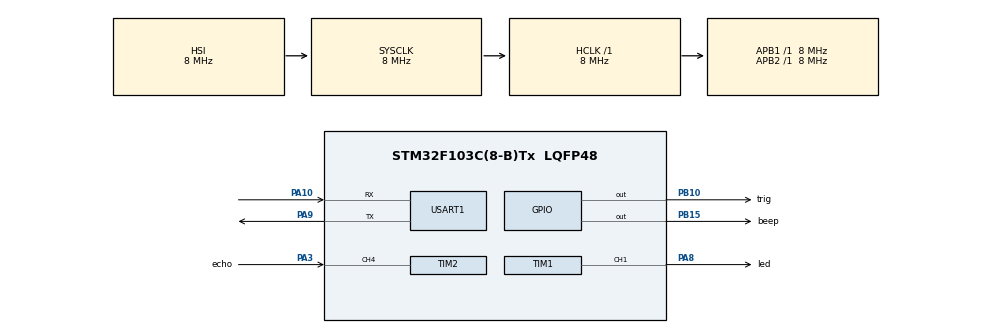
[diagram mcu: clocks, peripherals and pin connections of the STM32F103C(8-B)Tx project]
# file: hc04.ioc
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Mcu.Family=STM32F1
Mcu.Name=STM32F103C(8-B)Tx
Mcu.Package=LQFP48
NVIC.PriorityGroup=NVIC_PRIORITYGROUP_4
PA10.Mode=Asynchronous
PA10.Signal=USART1_RX
PA3.GPIO_Label=echo
PA3.Signal=S_TIM2_CH4
PA8.GPIO_Label=led
PA8.Signal=S_TIM1_CH1
PA9.Mode=Asynchronous
PA9.Signal=USART1_TX
PB10.GPIO_Label=trig
PB10.Signal=GPIO_Output
PB15.GPIO_Label=beep
PB15.Signal=GPIO_Output
ProjectManager.HeapSize=0x200
ProjectManager.StackSize=0x400
ProjectManager.TargetToolchain=MDK-ARM V5.32
RCC.AHBFreq_Value=8000000
RCC.APB1Freq_Value=8000000
RCC.APB1TimCLKDivider=1
RCC.APB1TimFreq_Value=8000000
RCC.APB2Freq_Value=8000000
RCC.APB2TimFreq_Value=8000000
RCC.HCLKFreq_Value=8000000
RCC.SYSCLKFreq_VALUE=8000000
RCC.USBFreq_Value=8000000
SH.S_TIM1_CH1.0=TIM1_CH1,Output Compare1 CH1
SH.S_TIM2_CH4.0=TIM2_CH4,Input_Capture4_from_TI4
TIM1.Channel-Output\ Compare1\ CH1=TIM_CHANNEL_1
TIM2.Channel-Input_Capture4_from_TI4=TIM_CHANNEL_4
TIM2.Prescaler=72-1
USART1.VirtualMode=VM_ASYNC
VP_SYS_VS_ND.Mode=No_Debug
board=custom

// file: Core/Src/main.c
/* USER CODE BEGIN Header */
/**
  ******************************************************************************
  * @file           : main.c
  * @brief          : Main program body
  ******************************************************************************
  * @attention
  *
  * Copyright (c) 2024 STMicroelectronics.
  * All rights reserved.
  *
  * This software is licensed under terms that can be found in the LICENSE file
  * in the root directory of this software component.
  * If no LICENSE file comes with this software, it is provided AS-IS.
  *
  ******************************************************************************
  */
/* USER CODE END Header */
#include "main.h"
#include "tim.h"
#include "usart.h"
#include "gpio.h"

/* USER CODE BEGIN Includes */
#include "hc-sr04.h"
#include "string.h"
#include <stdio.h>
/* USER CODE END Includes */

void SystemClock_Config(void);

int main(void)
{

  /* MCU Configuration--------------------------------------------------------*/

  /* Reset of all peripherals, Initializes the Flash interface and the Systick. */
  HAL_Init();

  /* Configure the system clock */
  SystemClock_Config();

  /* USER CODE BEGIN SysInit */
  Hcsr04Init(&htim2, TIM_CHANNEL_4);  //  鐡掑懎锛愬▔銏∧侀崸妤€鍨垫慨瀣

  /* USER CODE END SysInit */

  /* Initialize all configured peripherals */
  MX_GPIO_Init();
  MX_TIM1_Init();
  MX_TIM2_Init();
  MX_USART1_UART_Init();
  /* USER CODE BEGIN 2 */
  Hcsr04Start();  //  閿燂拷?閸氾拷鐡掑懎锛愬▔銏∧侀崸妤佺ゴ鐠猴拷
  /* USER CODE END 2 */

  /* Infinite loop */
  /* USER CODE BEGIN WHILE */
  float distance;
  while (1)
  {
    /* USER CODE END WHILE */
    distance = Hcsr04Read();
    log_distance(distance);
    Hcsr04Start();
    HAL_Delay(200);
  }
}
void log_distance(float distance) {
    char buffer[20]; // 缂傛挸鍟块崠鐚寸礉閻€劋绨€涙ê鍋嶉弽鐓庣础閸栨牜娈戠€涙锟斤缚瑕�
    sprintf(buffer, "distance:%.1f cm\r\n", distance); // 娴ｈ法鏁printf閺夈儲鐗稿蹇撳鐎涙锟斤缚瑕�
    HAL_UART_Transmit(&huart1, (uint8_t*)buffer, strlen(buffer), HAL_MAX_DELAY); // 閸欐垿鈧礁鐡х粭锔胯
}
void SystemClock_Config(void)
{
  RCC_OscInitTypeDef RCC_OscInitStruct = {0};
  RCC_ClkInitTypeDef RCC_ClkInitStruct = {0};

  /** Initializes the RCC Oscillators according to the specified parameters
  * in the RCC_OscInitTypeDef structure.
  */
  RCC_OscInitStruct.OscillatorType = RCC_OSCILLATORTYPE_HSI;
  RCC_OscInitStruct.HSIState = RCC_HSI_ON;
  RCC_OscInitStruct.HSICalibrationValue = RCC_HSICALIBRATION_DEFAULT;
  RCC_OscInitStruct.PLL.PLLState = RCC_PLL_NONE;
  if (HAL_RCC_OscConfig(&RCC_OscInitStruct) != HAL_OK)
  {
    Error_Handler();
  }

  /** Initializes the CPU, AHB and APB buses clocks
  */
  RCC_ClkInitStruct.ClockType = RCC_CLOCKTYPE_HCLK|RCC_CLOCKTYPE_SYSCLK
                              |RCC_CLOCKTYPE_PCLK1|RCC_CLOCKTYPE_PCLK2;
  RCC_ClkInitStruct.SYSCLKSource = RCC_SYSCLKSOURCE_HSI;
  RCC_ClkInitStruct.AHBCLKDivider = RCC_SYSCLK_DIV1;
  RCC_ClkInitStruct.APB1CLKDivider = RCC_HCLK_DIV1;
  RCC_ClkInitStruct.APB2CLKDivider = RCC_HCLK_DIV1;

  if (HAL_RCC_ClockConfig(&RCC_ClkInitStruct, FLASH_LATENCY_0) != HAL_OK)
  {
    Error_Handler();
  }
}

/* USER CODE BEGIN 4 */
/**
 * @description: 鐎规碍妞傞崳銊ㄧ翻閸戠儤宕熼懢铚傝厬閺傦拷
 * @param {TIM_HandleTypeDef} *htim
 * @return {*}
 */
void HAL_TIM_IC_CaptureCallback(TIM_HandleTypeDef *htim)
{
  Hcsr04TimIcIsr(htim);
}

/**
 * @description: 鐎规碍妞傞崳銊﹀閸戣桨鑵戦弬锟�
 * @param {*}
 * @return {*}
 */
void HAL_TIM_PeriodElapsedCallback(TIM_HandleTypeDef* htim)
{
  Hcsr04TimOverflowIsr(htim);
}

/* USER CODE END 4 */

void Error_Handler(void)
{
  __disable_irq();
  while (1)
  {
  }
}
